# STM32L4Q5xx register map
File version: 1.0
Registers are 32-bit, read-write, reset 0x0 unless marked. A register's access mark holds for its fields unless they carry their own. Offsets are from the block's base; [hi:lo] are bit positions; {n}, {i} and the like mark numbered series.

## TAMP — Tamper and backup registers
Base 0x40003400
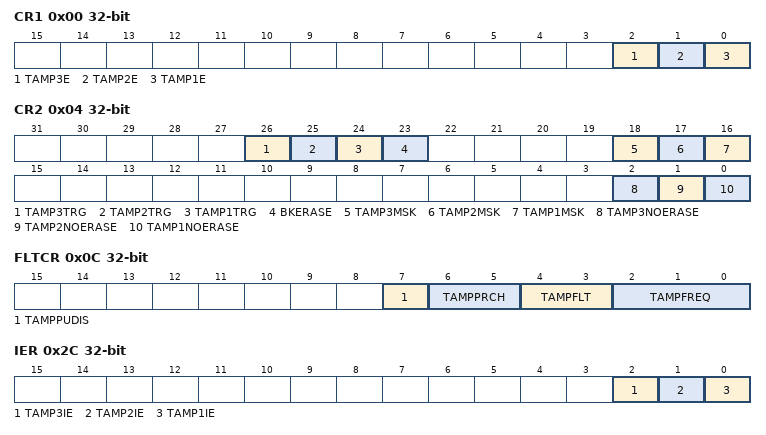
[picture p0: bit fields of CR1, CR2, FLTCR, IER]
0x00 CR1 — TAMP configuration register 1
  [2] TAMP3E, [1] TAMP2E, [0] TAMP1E
0x04 CR2 — TAMP configuration register 2
  [26] TAMP3TRG, [25] TAMP2TRG, [24] TAMP1TRG, [23] BKERASE, [18] TAMP3MSK, [17] TAMP2MSK, [16] TAMP1MSK, [2] TAMP3NOERASE, [1] TAMP2NOERASE, [0] TAMP1NOERASE
0x0C FLTCR — TAMP filter control register
  [7] TAMPPUDIS
  [6:5] TAMPPRCH
    0=DURATION_1RTCCLK (Tamper pins are pre-charged before sampling during 1 RTCCLK cycle); 1=DURATION_2RTCCLK (Tamper pins are pre-charged before sampling during 2 RTCCLK cycles); 2=DURATION_4RTCCLK (Tamper pins are pre-charged before sampling during 4 RTCCLK cycles); 3=DURATION_8RTCCLK (Tamper pins are pre-charged before sampling during 8 RTCCLK cycles)
  [4:3] TAMPFLT
    0=DISABLE (Tamper filter is disabled); 1=FILTER_2SAMPLE (Tamper is activated after 2 consecutive samples at the active level); 2=FILTER_4SAMPLE (Tamper is activated after 4 consecutive samples at the active level); 3=FILTER_8SAMPLE (Tamper is activated after 8 consecutive samples at the active level.)
  [2:0] TAMPFREQ
    0=SAMPLFREQDIV_32768 (Each of the tamper inputs are sampled with a frequency = RTCCLK / 32768); 1=SAMPLFREQDIV_16384 (Each of the tamper inputs are sampled with a frequency = RTCCLK / 16384); 2=SAMPLFREQDIV_8192 (Each of the tamper inputs are sampled with a frequency = RTCCLK / 8192); 3=SAMPLFREQDIV_4096 (Each of the tamper inputs are sampled with a frequency = RTCCLK / 4096); 4=SAMPLFREQDIV_2048 (Each of the tamper inputs are sampled with a frequency = RTCCLK / 2048); 5=SAMPLFREQDIV_1024 (Each of the tamper inputs are sampled with a frequency = RTCCLK / 1024); 6=SAMPLFREQDIV_512 (Each of the tamper inputs are sampled with a frequency = RTCCLK / 512); 7=SAMPLFREQDIV_256 (Each of the tamper inputs are sampled with a frequency = RTCCLK / 256)
0x2C IER — TAMP interrupt enable register
  [2] TAMP3IE, [1] TAMP2IE, [0] TAMP1IE
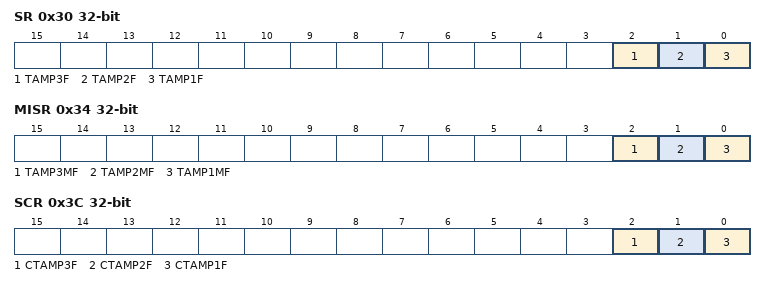
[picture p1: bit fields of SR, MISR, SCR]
0x30 SR — TAMP status register
  [2] TAMP3F, [1] TAMP2F, [0] TAMP1F
0x34 MISR — TAMP masked interrupt status register
  [2] TAMP3MF, [1] TAMP2MF, [0] TAMP1MF
0x3C SCR — TAMP status clear register
  [2] CTAMP3F, [1] CTAMP2F, [0] CTAMP1F
{0x100+4i} BKP{i}R (i=0..31) — TAMP backup register {i}

## SPI2 — Serial Peripheral Interface
Base 0x40003800
Same registers: SPI3 0x40003C00, SPI1 0x40013000
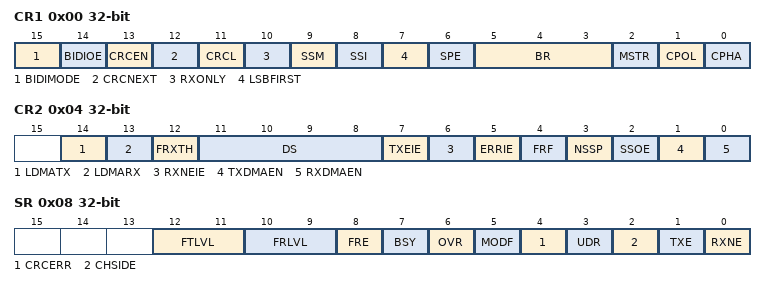
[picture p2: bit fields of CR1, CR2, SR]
0x00 CR1 — SPI Control register 1
  [15] BIDIMODE — Bidirectional data mode enable
  [14] BIDIOE — Output enable in bidirectional mode
  [13] CRCEN — Hardware CRC calculation enable
  [12] CRCNEXT — Transmit CRC next
  [11] CRCL — CRC Length
    0=CRC_8BIT (8-bit CRC length); 1=CRC_16BIT (16-bit CRC length)
  [10] RXONLY — Receive only
  [9] SSM — Software slave management
  [8] SSI — Internal slave select
  [7] LSBFIRST — Frame Format
    1=LSB_FIRST (Data is transmitted/received with the LSB first); 0=MSB_FIRST (Data is transmitted/received with the MSB first)
  [6] SPE — SPI Enable
  [5:3] BR — BR[2:0] bits (Baud Rate Control)
    0=DIV2 (BaudRate control equal to fPCLK/2); 1=DIV4 (BaudRate control equal to fPCLK/4); 2=DIV8 (BaudRate control equal to fPCLK/8); 3=DIV16 (BaudRate control equal to fPCLK/16); 4=DIV32 (BaudRate control equal to fPCLK/32); 5=DIV64 (BaudRate control equal to fPCLK/64); 6=DIV128 (BaudRate control equal to fPCLK/128); 7=DIV256 (BaudRate control equal to fPCLK/256)
  [2] MSTR — Master Selection
  [1] CPOL — Clock Polarity
    0=LOW (Clock to 0 when idle); 1=HIGH (Clock to 1 when idle)
  [0] CPHA — Clock Phase
    0=PHASE_1EDGE (First clock transition is the first data capture edge); 1=PHASE_2EDGE (Second clock transition is the first data capture edge)
0x04 CR2 — SPI Control register 2
  [14] LDMATX — Last DMA transfer for transmission
  [13] LDMARX — Last DMA transfer for reception
  [12] FRXTH — FIFO reception Threshold
    0=HALF (RXNE event is generated if FIFO level is greater than or equal to 1/2 (16-bit)); 1=QUARTER (RXNE event is generated if FIFO level is greater than or equal to 1/4 (8-bit))
  [11:8] DS — DS[3:0] Data Size
    {v}=DATAWIDTH_{v+1}BIT (Data length for SPI transfer: {v+1} bits) (v=3..15)
  [7] TXEIE — Tx buffer Empty Interrupt Enable
  [6] RXNEIE — RX buffer Not Empty Interrupt Enable
  [5] ERRIE — Error Interrupt Enable
  [4] FRF — Frame Format Enable
    0=MOTOROLA (Motorola mode. Used as default value); 1=TI (TI mode)
  [3] NSSP — NSS pulse management Enable
  [2] SSOE — SS Output Enable
  [1] TXDMAEN — Tx Buffer DMA Enable
  [0] RXDMAEN — Rx Buffer DMA Enable
0x08 SR — SPI Status register
  [12:11] FTLVL — FIFO Transmission Level
    0=EMPTY (FIFO transmission empty); 1=QUARTER_FULL (FIFO transmission 1/4); 2=HALF_FULL (FIFO transmission 1/2); 3=FULL (FIFO transmission full)
  [10:9] FRLVL — FIFO Reception Level
    0=EMPTY (FIFO reception empty); 1=QUARTER_FULL (FIFO reception 1/4); 2=HALF_FULL (FIFO reception 1/2); 3=FULL (FIFO reception full)
  [8] FRE — TI frame format error
  [7] BSY — Busy flag
  [6] OVR — Overrun flag
  [5] MODF — Mode fault
  [4] CRCERR — CRC Error flag
  [3] UDR — Underrun flag
  [2] CHSIDE — Channel side
  [1] TXE — Transmit buffer Empty
  [0] RXNE — Receive buffer Not Empty
0x0C DR — SPI data register
  [15:0] DR — Data Register
0x10 CRCPR — SPI CRC polynomial register
  [15:0] CRCPOLY — CRC polynomial register
0x14 RXCRCR — SPI Rx CRC register
  [15:0] RXCRC
0x18 TXCRCR — SPI Tx CRC register
  [15:0] TXCRC
